# XMC1400 register map
Vendor: Infineon; File version: 1.0.5 (Reference Manual v1.0)
CPU: CM0 r0p0, little endian, no MPU, no FPU, 2 interrupt priority bits
Registers are 32-bit, read-write, reset 0x0 unless marked. A register's access mark holds for its fields unless they carry their own. Offsets are from the block's base; [hi:lo] are bit positions; {n}, {i} and the like mark numbered series.

## SCU_CLK — System Control Unit
Base 0x40010300
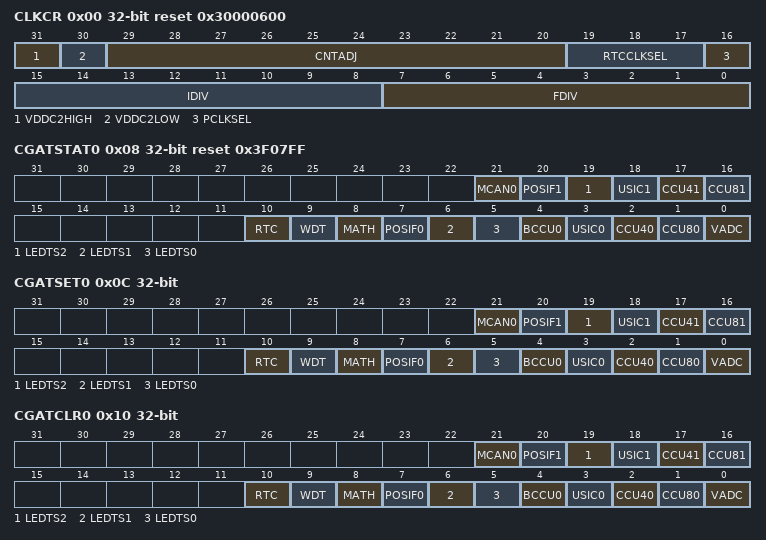
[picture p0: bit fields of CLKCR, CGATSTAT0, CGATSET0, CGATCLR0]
0x00 CLKCR access per field reset 0x30000600 — Clock Control Register
  [31] VDDC2HIGH ro — VDDC too high
    0=VDDC is not too high; 1=VDDC is too high
  [30] VDDC2LOW ro — VDDC too low
    0=VDDC is not too low and the fractional divider input clock is running at the targeted frequency; 1=VDDC is too low and the fractional divider input clock is not running at the targeted frequency
  [29:20] CNTADJ rw — Counter Adjustment
    {v}={v+1} clock cycles of the DCO1, 48MHz clock (v=0..4); 0x300=769 clock cycles of the DCO1, 48MHz clock; 0x3FE=1023 clock cycles of the DCO1, 48MHz clock; 0x3FF=1024 clock cycles of the DCO1, 48MHz clock
  [19:17] RTCCLKSEL rw — RTC Clock Select
  [16] PCLKSEL rw — PCLK Clock Select
    0=PCLK = MCLK; 1=PCLK = 2 x MCLK
  [15:8] IDIV rw — Divider Selection
    0=Divider is bypassed; {v}={v}; (v=1..4); 254=254;; 255=255;
  [7:0] FDIV rw — Fractional Divider Selection, FDIV[7:0]
0x04 PWRSVCR — Power Save Control Register
  [0] FPD — Flash Power Down
    0=no effect; 1=Flash power down when entering power save mode. Upon wake-up, CPU is able to fetch code from flash.
0x08 CGATSTAT0 ro reset 0x3F07FF — Peripheral 0 Clock Gating Status
  [all] fields
    0=gating de-asserted; 1=gating asserted
  [21] MCAN0 — MultiCAN Gating Status
  [20] POSIF1 — POSIF1 Gating Status
  [19] LEDTS2 — LEDTS2 Gating Status
  [18] USIC1 — USIC1 Gating Status
  [17] CCU41 — CCU41 Gating Status
  [16] CCU81 — CCU81 Gating Status
  [10] RTC — RTC Gating Status
  [9] WDT — WDT Gating Status
  [8] MATH — MATH Gating Status
  [7] POSIF0 — POSIF0 Gating Status
  [6] LEDTS1 — LEDTS1 Gating Status
  [5] LEDTS0 — LEDTS0 Gating Status
  [4] BCCU0 — BCCU0 Gating Status
  [3] USIC0 — USIC0 Gating Status
  [2] CCU40 — CCU40 Gating Status
  [1] CCU80 — CCU80 Gating Status
  [0] VADC — VADC and SHS Gating Status
0x0C CGATSET0 wo — Peripheral 0 Clock Gating Set
  [all] fields
    0=no effect; 1=enable gating
  [21] MCAN0 — MutliCAN Gating Set
  [20] POSIF1 — POSIF1 Gating Set
  [19] LEDTS2 — LEDTS2 Gating Set
  [18] USIC1 — USIC1 Gating Set
  [17] CCU41 — CCU41 Gating Set
  [16] CCU81 — CCU81 Gating Set
  [10] RTC — RTC Gating Set
  [9] WDT — WDT Gating Set
  [8] MATH — MATH Gating Set
  [7] POSIF0 — POSIF0 Gating Set
  [6] LEDTS1 — LEDTS1 Gating Set
  [5] LEDTS0 — LEDTS0 Gating Set
  [4] BCCU0 — BCCU0 Gating Set
  [3] USIC0 — USIC0 Gating Set
  [2] CCU40 — CCU40 Gating Set
  [1] CCU80 — CCU80 Gating Set
  [0] VADC — VADC and SHS Gating Set
0x10 CGATCLR0 wo — Peripheral 0 Clock Gating Clear
  [21] MCAN0 — MutliCAN Gating Clear
    0=no effect; 1=disable gating
  [20] POSIF1 — POSIF1 Gating Clear
    0=no effect; 1=disable gating
  [19] LEDTS2 — LEDTS2 Gating Clear
    0=no effect; 1=disable gating
  [18] USIC1 — USIC1 Gating Clear
    0=no effect; 1=disable gating
  [17] CCU41 — CCU41 Gating Clear
    0=no effect; 1=disable gating
  [16] CCU81 — CCU81 Gating Clear
    0=no effect; 1=disable gating
  [10] RTC — RTC Gating Clear
    0=no effect; 1=disable gating
  [9] WDT — WDT Gating Clear
    0=no effect; 1=disble gating
  [8] MATH — MATH Gating Clear
    0=no effect; 1=disable gating
  [7] POSIF0 — POSIF0 Gating Clear
    0=no effect; 1=disable gating
  [6] LEDTS1 — LEDTS1 Gating Clear
    0=no effect; 1=disable gating
  [5] LEDTS0 — LEDTS0 Gating Clear
    0=no effect; 1=disable gating
  [4] BCCU0 — BCCU0 Gating Clear
    0=no effect; 1=disable gating
  [3] USIC0 — USIC0 Gating Clear
    0=no effect; 1=disable gating
  [2] CCU40 — CCU40 Gating Clear
    0=no effect; 1=disable gating
  [1] CCU80 — CCU80 Gating Clear
    0=no effect; 1=disble gating
  [0] VADC — VADC and SHS Gating Clear
    0=no effect; 1=disable gating
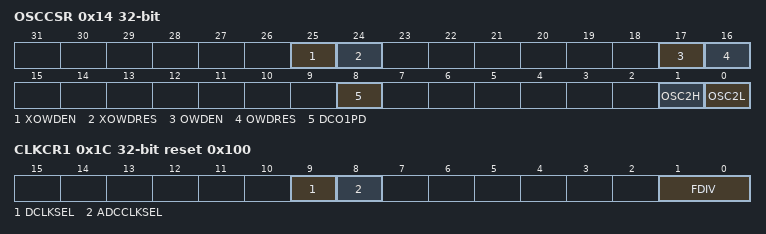
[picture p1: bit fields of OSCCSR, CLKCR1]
0x14 OSCCSR access per field (reset mask 0xFFFFFFF0) — Oscillator Control and Status Register
  [25] XOWDEN rw — XTAL Oscillator Watchdog Enable
    0=The XTAL Oscillator Watchdog is disabled; 1=The XTAL Oscillator Watchdog is enabled
  [24] XOWDRES rw — XTAL Oscillator Watchdog Reset
    0=The Oscillator Watchdog is not cleared and remains active; 1=The Oscillator Watchdog is cleared and restarted
  [17] OWDEN rw — Oscillator Watchdog Enable
    0=The Oscillator Watchdog is disabled; 1=The Oscillator Watchdog is enabled
  [16] OWDRES rw — Oscillator Watchdog Reset
    0=The Oscillator Watchdog is not cleared and remains active; 1=The Oscillator Watchdog is cleared and restarted. The OSC2L and OSC2H flag will be held in the last value until it is updated after 3 standby clock cycles.
  [8] DCO1PD rw — DCO1 Power down
    0=DCO1 is not power down; 1=DCO1 power down
  [1] OSC2H ro — Oscillator Valid High Status Bit
    0=The OSC frequency is usable; 1=The OSC frequency is not usable. Frequency is too high.
  [0] OSC2L ro — Oscillator Valid Low Status Bit
    0=The OSC frequency is usable; 1=The OSC frequency is not usable. Frequency is too low.
0x1C CLKCR1 reset 0x100 — Clock Control Register 1
  [9] DCLKSEL — Doubler Clock Source Select
    0=DCO1; 1=External clock via OSC_HP
  [8] ADCCLKSEL — ADC Converter Clock Select
    0=fCONV= 48MHz; 1=fCONV= 32MHz
  [1:0] FDIV — Fractional Divider Selection, FDIV[9:8]

## Notices in the file
Copyright (C) 2012 Infineon Technologies AG. All rights reserved.
Infineon Technologies AG (Infineon) is supplying this software for use with
Infineon's microcontrollers.  This file can be freely distributed within
development tools that are supporting such microcontrollers.
THIS SOFTWARE IS PROVIDED "AS IS".  NO WARRANTIES, WHETHER EXPRESS, IMPLIED
OR STATUTORY, INCLUDING, BUT NOT LIMITED TO, IMPLIED WARRANTIES OF
MERCHANTABILITY AND FITNESS FOR A PARTICULAR PURPOSE APPLY TO THIS SOFTWARE.
INFINEON SHALL NOT, IN ANY CIRCUMSTANCES, BE LIABLE FOR SPECIAL, INCIDENTAL,
OR CONSEQUENTIAL DAMAGES, FOR ANY REASON WHATSOEVER.
